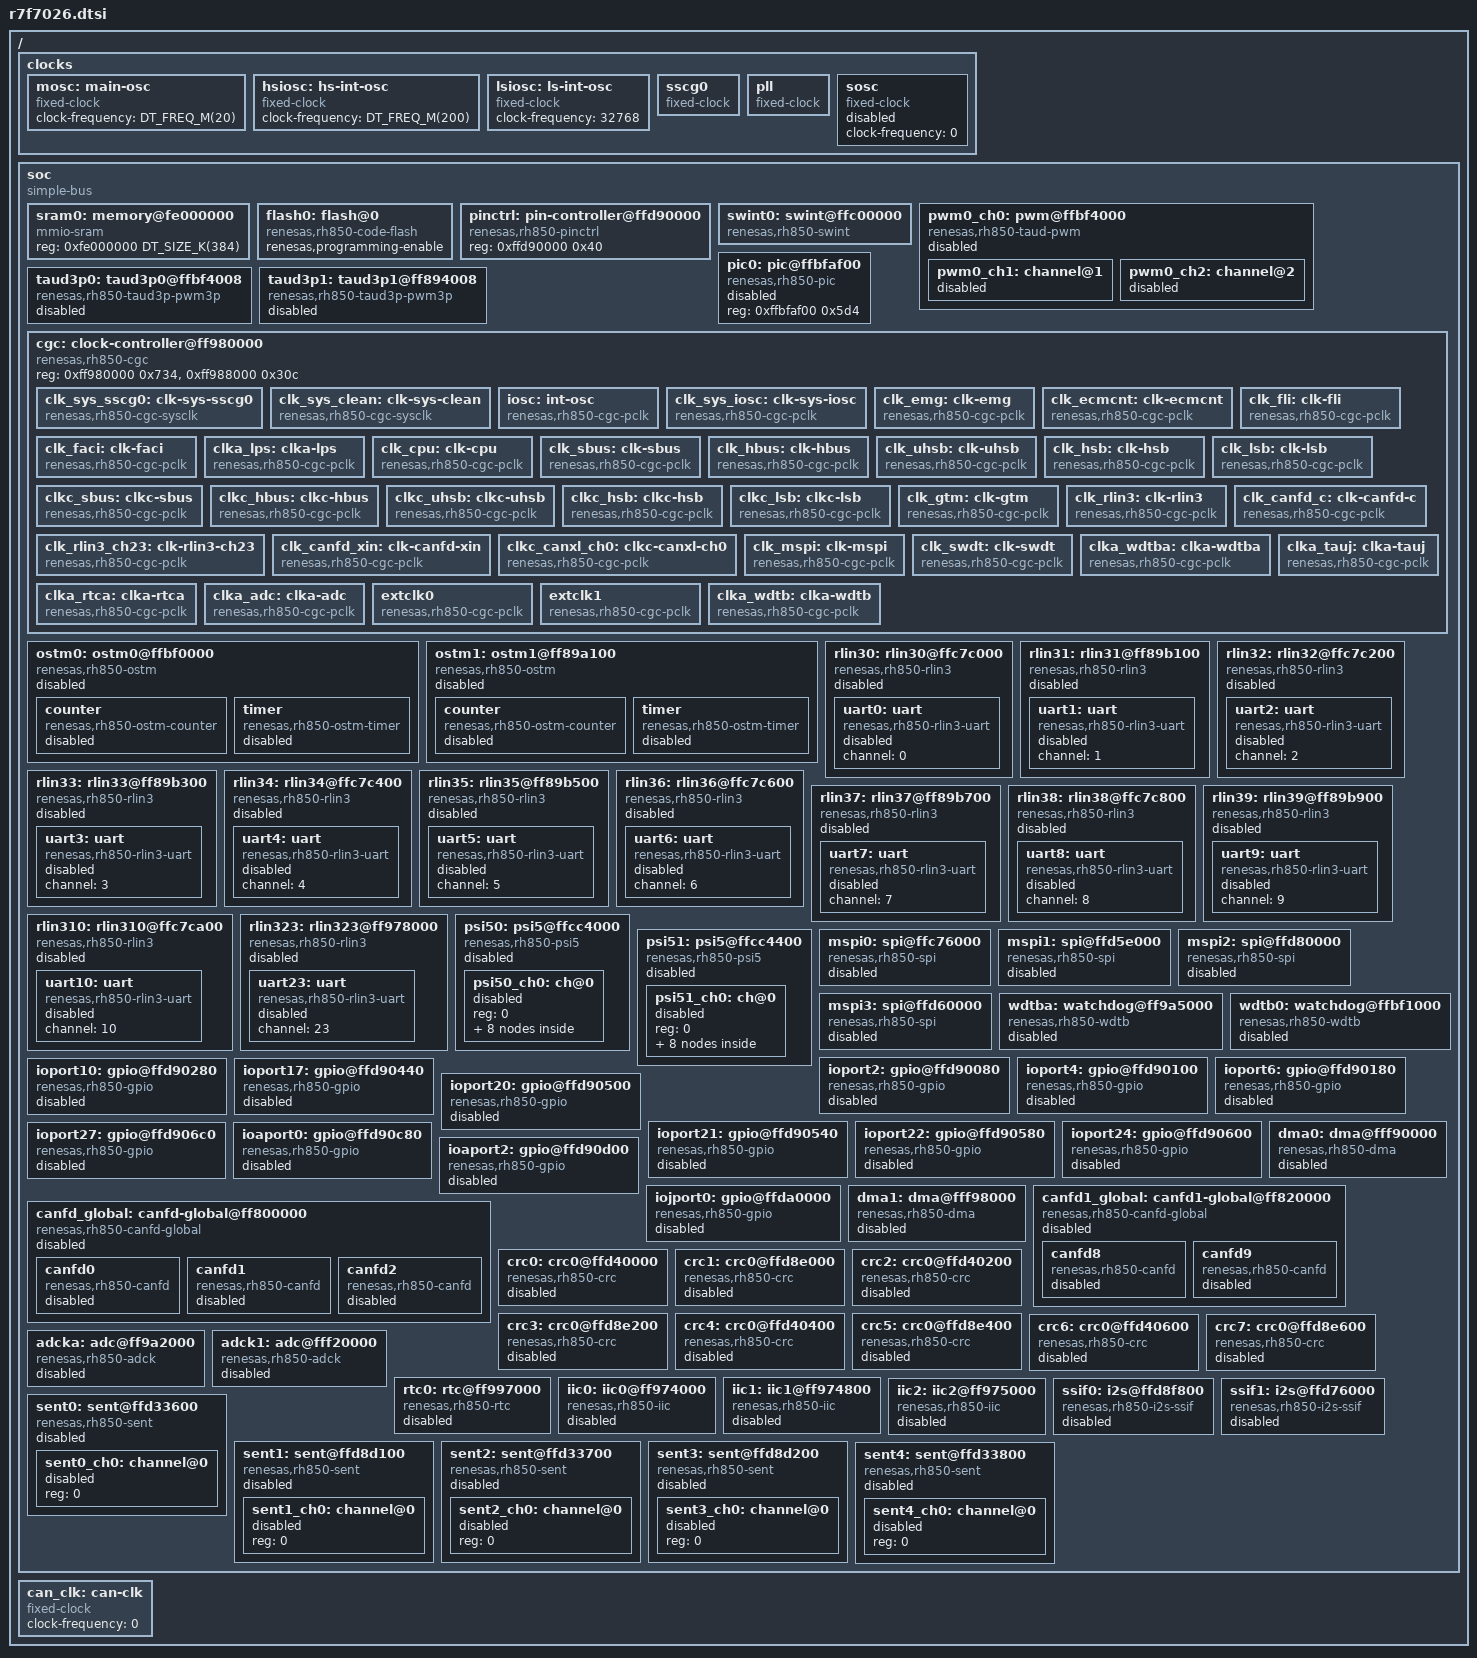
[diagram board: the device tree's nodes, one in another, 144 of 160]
/*
 * Copyright (c) 2026 Renesas Electronics Corporation
 *
 * SPDX-License-Identifier: Apache-2.0
 */

#include <rh850/renesas/rh850u2c/u2c-g4kh-common.dtsi>
#include <zephyr/dt-bindings/clock/renesas_rh850u2c_clock.h>
#include <zephyr/dt-bindings/gpio/gpio.h>
#include <freq.h>

/ {
	clocks {
		mosc: main-osc {
			compatible = "fixed-clock";
			#clock-cells = <0>;
			status = "okay";
			clock-frequency = <DT_FREQ_M(20)>;
		};

		hsiosc: hs-int-osc {
			compatible = "fixed-clock";
			#clock-cells = <0>;
			status = "okay";
			clock-frequency = <DT_FREQ_M(200)>;
		};

		lsiosc: ls-int-osc {
			compatible = "fixed-clock";
			#clock-cells = <0>;
			status = "okay";
			clock-frequency = <32768>;
		};

		sscg0: sscg0 {
			compatible = "fixed-clock";
			#clock-cells = <0>;
			status = "okay";
			clock-frequency = <DT_FREQ_M(640)>;
			clocks = <&mosc>;
		};

		pll: pll {
			compatible = "fixed-clock";
			#clock-cells = <0>;
			status = "okay";
			clock-frequency = <DT_FREQ_M(800)>;
			clocks = <&mosc>;
		};

		sosc: sosc {
			compatible = "fixed-clock";
			#clock-cells = <0>;
			status = "disabled";
			clock-frequency = <0>;
		};
	};

	soc {
		#address-cells = <1>;
		#size-cells = <1>;
		compatible = "simple-bus";
		ranges;

		sram0: memory@fe000000 {
			compatible = "mmio-sram";
			reg = <0xfe000000 DT_SIZE_K(384)>;
		};

		flash0: flash@0 {
			compatible = "renesas,rh850-code-flash";
			renesas,programming-enable;
		};

		pinctrl: pin-controller@ffd90000 {
			compatible = "renesas,rh850-pinctrl";
			reg = <0xffd90000 0x40>;
			status = "okay";
		};

		swint0: swint@ffc00000 {
			compatible = "renesas,rh850-swint";
			reg = <0xffc00000 0x01>;
			interrupts-extended = <&intc1_pe0 14 14>,
					      <&intc1_pe1 14 14>;
			interrupt-names = "swint_pe0", "swint_pe1";
			status = "okay";
		};

		pwm0_ch0: pwm@ffbf4000 {
			compatible = "renesas,rh850-taud-pwm";
			reg = <0xffbf4000 0x100>;
			unit = <0>;
			channel = <0>;
			interrupt-parent = <&intc1_pe0>;
			clocks = <&cgc RH850_PCLK(TAUD, 0, PCLK)>;
			clock-source = <0>;
			clock-divider = <5>;
			interrupts = <10 1>;
			#pwm-cells = <3>;
			#address-cells = <1>;
			#size-cells = <0>;
			status = "disabled";

			pwm0_ch1: channel@1 {
				reg = <1>;
				channel-mode = "synchronized";
				status = "disabled";
			};

			pwm0_ch2: channel@2 {
				reg = <2>;
				channel-mode = "synchronized";
				status = "disabled";
			};
		};

		pic0: pic@ffbfaf00 {
			compatible = "renesas,rh850-pic";
			reg = <0xffbfaf00 0x5d4>;
			status = "disabled";
		};

		taud3p0: taud3p0@ffbf4008 {
			compatible = "renesas,rh850-taud3p-pwm3p";
			reg = <0xffbf4008 0x2000>;
			taud-three-phase-unit = <0>;
			clocks = <&cgc RH850_PCLK(TAUD, 0, PCLK)>;
			period-counts = <0xfa0>;
			deadtime-counts = <240>;
			operation-clk = <0>;
			clk-div = <0>;
			interrupts = <11 1>;
			interrupt-parent = <&intc2>;
			status = "disabled";
		};

		taud3p1: taud3p1@ff894008 {
			compatible = "renesas,rh850-taud3p-pwm3p";
			reg = <0xff894008 0x2000>;
			taud-three-phase-unit = <1>;
			clocks = <&cgc RH850_PCLK(TAUD, 1, PCLK)>;
			period-counts = <0xfa0>;
			deadtime-counts = <240>;
			operation-clk = <0>;
			clk-div = <0>;
			interrupts = <159 1>;
			interrupt-parent = <&intc2>;
			status = "disabled";
		};

		cgc: clock-controller@ff980000 {
			compatible = "renesas,rh850-cgc";
			reg = <0xff980000 0x734>, <0xff988000 0x30c>;
			#clock-cells = <1>;
			status = "okay";

			clk_sys_sscg0: clk-sys-sscg0 {
				compatible = "renesas,rh850-cgc-sysclk";
				clock-source = <&sscg0>;
				#clock-cells = <0>;
				status = "okay";
				modulation-value = <30>;
				modulation-dithered-range = <0>;
				renesas,cyclicrun-clock-source = <&clk_sys_iosc>;
				div = <1>;
				renesas,cyclicrun-div = <1>;
			};

			clk_sys_clean: clk-sys-clean {
				compatible = "renesas,rh850-cgc-sysclk";
				clock-source = <&pll>;
				#clock-cells = <0>;
				status = "okay";
				renesas,cyclicrun-clock-source = <&clk_sys_iosc>;
				div = <1>;
				renesas,cyclicrun-div = <1>;
			};

			iosc: int-osc {
				compatible = "renesas,rh850-cgc-pclk";
				#clock-cells = <0>;
				status = "okay";
				clock-source = <&hsiosc>;
				div = <1>;
			};

			clk_sys_iosc: clk-sys-iosc {
				compatible = "renesas,rh850-cgc-pclk";
				#clock-cells = <0>;
				status = "okay";
				clock-source = <&hsiosc>;
				div = <1>;
			};

			clk_emg: clk-emg {
				compatible = "renesas,rh850-cgc-pclk";
				#clock-cells = <0>;
				status = "okay";
				clock-source = <&hsiosc>;
				renesas,cyclicrun-clock-source = <&hsiosc>;
				div = <20>;
				renesas,cyclicrun-div = <20>;
			};

			clk_ecmcnt: clk-ecmcnt {
				compatible = "renesas,rh850-cgc-pclk";
				#clock-cells = <0>;
				status = "okay";
				clock-source = <&hsiosc>;
				div = <20>;
			};

			clk_fli: clk-fli {
				compatible = "renesas,rh850-cgc-pclk";
				#clock-cells = <0>;
				status = "okay";
				clock-source = <&clk_cpu>;
				div = <1>;
			};

			clk_faci: clk-faci {
				compatible = "renesas,rh850-cgc-pclk";
				#clock-cells = <0>;
				status = "okay";
				clock-source = <&clk_lsb>;
				div = <1>;
			};

			clka_lps: clka-lps {
				compatible = "renesas,rh850-cgc-pclk";
				#clock-cells = <0>;
				status = "okay";
				clock-source = <&hsiosc>;
				div = <20>;
			};

			clk_cpu: clk-cpu {
				compatible = "renesas,rh850-cgc-pclk";
				#clock-cells = <0>;
				status = "okay";
				clock-source = <&clk_sys_sscg0>;
				div = <2>;
			};

			clk_sbus: clk-sbus {
				compatible = "renesas,rh850-cgc-pclk";
				#clock-cells = <0>;
				status = "okay";
				clock-source = <&clk_sys_sscg0>;
				div = <4>;
			};

			clk_hbus: clk-hbus {
				compatible = "renesas,rh850-cgc-pclk";
				#clock-cells = <0>;
				status = "okay";
				clock-source = <&clk_sys_sscg0>;
				div = <8>;
			};

			clk_uhsb: clk-uhsb {
				compatible = "renesas,rh850-cgc-pclk";
				#clock-cells = <0>;
				status = "okay";
				clock-source = <&clk_sys_sscg0>;
				div = <4>;
			};

			clk_hsb: clk-hsb {
				compatible = "renesas,rh850-cgc-pclk";
				#clock-cells = <0>;
				status = "okay";
				clock-source = <&clk_sys_sscg0>;
				div = <8>;
			};

			clk_lsb: clk-lsb {
				compatible = "renesas,rh850-cgc-pclk";
				#clock-cells = <0>;
				status = "okay";
				clock-source = <&clk_sys_sscg0>;
				div = <16>;
			};

			clkc_sbus: clkc-sbus {
				compatible = "renesas,rh850-cgc-pclk";
				#clock-cells = <0>;
				status = "okay";
				clock-source = <&clk_sys_clean>;
				div = <4>;
			};

			clkc_hbus: clkc-hbus {
				compatible = "renesas,rh850-cgc-pclk";
				#clock-cells = <0>;
				status = "okay";
				clock-source = <&clk_sys_clean>;
				div = <8>;
			};

			clkc_uhsb: clkc-uhsb {
				compatible = "renesas,rh850-cgc-pclk";
				#clock-cells = <0>;
				status = "okay";
				clock-source = <&clk_sys_clean>;
				div = <5>;
			};

			clkc_hsb: clkc-hsb {
				compatible = "renesas,rh850-cgc-pclk";
				#clock-cells = <0>;
				status = "okay";
				clock-source = <&clk_sys_clean>;
				div = <10>;
			};

			clkc_lsb: clkc-lsb {
				compatible = "renesas,rh850-cgc-pclk";
				#clock-cells = <0>;
				status = "okay";
				clock-source = <&clk_sys_clean>;
				div = <20>;
			};

			clk_gtm: clk-gtm {
				compatible = "renesas,rh850-cgc-pclk";
				#clock-cells = <0>;
				status = "okay";
				clock-source = <&clkc_sbus>;
				div = <1>;
			};

			clk_rlin3: clk-rlin3 {
				compatible = "renesas,rh850-cgc-pclk";
				clock-source = <&clkc_hsb>;
				#clock-cells = <0>;
				status = "okay";
				renesas,cyclicrun-clock-source = <&clkc_hsb>;
				div = <1>;
				renesas,cyclicrun-div = <1>;
			};

			clk_rlin3_ch23: clk-rlin3-ch23 {
				compatible = "renesas,rh850-cgc-pclk";
				clock-source = <&clkc_hbus>;
				#clock-cells = <0>;
				status = "okay";
				renesas,cyclicrun-clock-source = <&clkc_hbus>;
				div = <1>;
				renesas,cyclicrun-div = <1>;
			};

			clk_canfd_c: clk-canfd-c {
				compatible = "renesas,rh850-cgc-pclk";
				clock-source = <&clkc_hsb>;
				#clock-cells = <0>;
				status = "okay";
				div = <1>;
			};

			clk_canfd_xin: clk-canfd-xin {
				compatible = "renesas,rh850-cgc-pclk";
				clock-source = <&mosc>;
				#clock-cells = <0>;
				status = "okay";
				div = <1>;
			};

			clkc_canxl_ch0: clkc-canxl-ch0 {
				compatible = "renesas,rh850-cgc-pclk";
				clock-source = <&clkc_hsb>;
				#clock-cells = <0>;
				status = "okay";
				div = <1>;
			};

			clk_mspi: clk-mspi {
				compatible = "renesas,rh850-cgc-pclk";
				clock-source = <&clkc_hsb>;
				#clock-cells = <0>;
				status = "okay";
				renesas,cyclicrun-clock-source = <&clkc_hsb>;
				div = <1>;
				renesas,cyclicrun-div = <1>;
			};

			clk_swdt: clk-swdt {
				compatible = "renesas,rh850-cgc-pclk";
				clock-source = <&hsiosc>;
				#clock-cells = <0>;
				status = "okay";
				div = <20>;
			};

			clka_wdtba: clka-wdtba {
				compatible = "renesas,rh850-cgc-pclk";
				clock-source = <&lsiosc>;
				#clock-cells = <0>;
				status = "okay";
				renesas,cyclicrun-clock-source = <&lsiosc>;
				div = <128>;
				renesas,cyclicrun-div = <128>;
			};

			clka_tauj: clka-tauj {
				compatible = "renesas,rh850-cgc-pclk";
				clock-source = <&lsiosc>;
				#clock-cells = <0>;
				status = "okay";
				renesas,cyclicrun-clock-source = <&lsiosc>;
				div = <1>;
				renesas,cyclicrun-div = <1>;
			};

			clka_rtca: clka-rtca {
				compatible = "renesas,rh850-cgc-pclk";
				clock-source = <&lsiosc>;
				#clock-cells = <0>;
				status = "okay";
				renesas,cyclicrun-clock-source = <&lsiosc>;
				div = <1>;
				renesas,cyclicrun-div = <1>;
			};

			clka_adc: clka-adc {
				compatible = "renesas,rh850-cgc-pclk";
				clock-source = <&hsiosc>;
				#clock-cells = <0>;
				status = "okay";
				renesas,cyclicrun-clock-source = <&hsiosc>;
				div = <20>;
				renesas,cyclicrun-div = <20>;
			};

			extclk0: extclk0 {
				compatible = "renesas,rh850-cgc-pclk";
				clock-source = <&clk_hsb>;
				div = <0>;
				#clock-cells = <0>;
				status = "okay";
				renesas,cyclicrun-div = <0>;
				renesas,cyclicrun-clock-source = <&clk_hsb>;
			};

			extclk1: extclk1 {
				compatible = "renesas,rh850-cgc-pclk";
				clock-source = <&clk_hsb>;
				div = <0>;
				#clock-cells = <0>;
				status = "okay";
				renesas,cyclicrun-div = <0>;
				renesas,cyclicrun-clock-source = <&clk_hsb>;
			};

			clka_wdtb: clka-wdtb {
				compatible = "renesas,rh850-cgc-pclk";
				clock-source = <&hsiosc>;
				#clock-cells = <0>;
				status = "okay";
				div = <640>;
				renesas,cyclicrun-clock-source = <&hsiosc>;
				renesas,cyclicrun-div = <640>;
			};
		};

		ostm0: ostm0@ffbf0000 {
			compatible = "renesas,rh850-ostm";
			reg = <0xffbf0000 0x20>;
			channel = <0>;
			interrupts = <63 1>;
			interrupt-names = "overflow";
			interrupt-parent = <&intc2>;
			clocks = <&cgc RH850_PCLK(OSTM, 0, PCLK)>;
			status = "disabled";

			counter {
				compatible = "renesas,rh850-ostm-counter";
				status = "disabled";
			};

			timer {
				compatible = "renesas,rh850-ostm-timer";
				status = "disabled";
			};
		};

		ostm1: ostm1@ff89a100 {
			compatible = "renesas,rh850-ostm";
			reg = <0xff89a100 0x20>;
			channel = <1>;
			interrupts = <484 1>;
			interrupt-names = "overflow";
			interrupt-parent = <&intc2>;
			clocks = <&cgc RH850_PCLK(OSTM, 1, PCLK)>;
			status = "disabled";

			counter {
				compatible = "renesas,rh850-ostm-counter";
				status = "disabled";
			};

			timer {
				compatible = "renesas,rh850-ostm-timer";
				status = "disabled";
			};
		};

		rlin30: rlin30@ffc7c000 {
			compatible = "renesas,rh850-rlin3";
			interrupts = <173 1>, <174 1>, <175 1>, <176 1>;
			interrupt-names = "rlin3i", "txi", "rxi", "eri";
			reg = <0xffc7c000 0x35>;
			interrupt-parent = <&intc2>;
			clocks = <&cgc RH850_PCLK(RLIN3, 0, RLIN3)>;
			status = "disabled";

			uart0: uart {
				compatible = "renesas,rh850-rlin3-uart";
				channel = <0>;
				status = "disabled";
			};
		};

		rlin31: rlin31@ff89b100 {
			compatible = "renesas,rh850-rlin3";
			interrupts = <178 1>, <179 1>, <180 1>, <181 1>;
			interrupt-names = "rlin3i", "txi", "rxi", "eri";
			reg = <0xff89b100 0x35>;
			interrupt-parent = <&intc2>;
			clocks = <&cgc RH850_PCLK(RLIN3, 1, RLIN3)>;
			status = "disabled";

			uart1: uart {
				compatible = "renesas,rh850-rlin3-uart";
				channel = <1>;
				status = "disabled";
			};
		};

		rlin32: rlin32@ffc7c200 {
			compatible = "renesas,rh850-rlin3";
			interrupts = <183 1>, <184 1>, <185 1>, <186 1>;
			interrupt-names = "rlin3i", "txi", "rxi", "eri";
			reg = <0xffc7c200 0x35>;
			interrupt-parent = <&intc2>;
			clocks = <&cgc RH850_PCLK(RLIN3, 2, RLIN3)>;
			status = "disabled";

			uart2: uart {
				compatible = "renesas,rh850-rlin3-uart";
				channel = <2>;
				status = "disabled";
			};
		};

		rlin33: rlin33@ff89b300 {
			compatible = "renesas,rh850-rlin3";
			interrupts = <188 1>, <189 1>, <190 1>, <191 1>;
			interrupt-names = "rlin3i", "txi", "rxi", "eri";
			reg = <0xff89b300 0x35>;
			interrupt-parent = <&intc2>;
			clocks = <&cgc RH850_PCLK(RLIN3, 3, RLIN3)>;
			status = "disabled";

			uart3: uart {
				compatible = "renesas,rh850-rlin3-uart";
				channel = <3>;
				status = "disabled";
			};
		};

		rlin34: rlin34@ffc7c400 {
			compatible = "renesas,rh850-rlin3";
			interrupts = <193 1>, <194 1>, <195 1>, <196 1>;
			interrupt-names = "rlin3i", "txi", "rxi", "eri";
			reg = <0xffc7c400 0x35>;
			interrupt-parent = <&intc2>;
			clocks = <&cgc RH850_PCLK(RLIN3, 4, RLIN3)>;
			status = "disabled";

			uart4: uart {
				compatible = "renesas,rh850-rlin3-uart";
				channel = <4>;
				status = "disabled";
			};
		};

		rlin35: rlin35@ff89b500 {
			compatible = "renesas,rh850-rlin3";
			interrupts = <197 1>, <198 1>, <199 1>, <200 1>;
			interrupt-names = "rlin3i", "txi", "rxi", "eri";
			reg = <0xff89b500 0x35>;
			interrupt-parent = <&intc2>;
			clocks = <&cgc RH850_PCLK(RLIN3, 5, RLIN3)>;
			status = "disabled";

			uart5: uart {
				compatible = "renesas,rh850-rlin3-uart";
				channel = <5>;
				status = "disabled";
			};
		};

		rlin36: rlin36@ffc7c600 {
			compatible = "renesas,rh850-rlin3";
			interrupts = <201 1>, <202 1>, <203 1>, <204 1>;
			interrupt-names = "rlin3i", "txi", "rxi", "eri";
			reg = <0xffc7c600 0x35>;
			interrupt-parent = <&intc2>;
			clocks = <&cgc RH850_PCLK(RLIN3, 6, RLIN3)>;
			status = "disabled";

			uart6: uart {
				compatible = "renesas,rh850-rlin3-uart";
				channel = <6>;
				status = "disabled";
			};
		};

		rlin37: rlin37@ff89b700 {
			compatible = "renesas,rh850-rlin3";
			interrupts = <394 1>, <395 1>, <396 1>, <397 1>;
			interrupt-names = "rlin3i", "txi", "rxi", "eri";
			reg = <0xff89b700 0x35>;
			interrupt-parent = <&intc2>;
			clocks = <&cgc RH850_PCLK(RLIN3, 7, RLIN3)>;
			status = "disabled";

			uart7: uart {
				compatible = "renesas,rh850-rlin3-uart";
				channel = <7>;
				status = "disabled";
			};
		};

		rlin38: rlin38@ffc7c800 {
			compatible = "renesas,rh850-rlin3";
			interrupts = <398 1>, <399 1>, <400 1>, <401 1>;
			interrupt-names = "rlin3i", "txi", "rxi", "eri";
			reg = <0xffc7c800 0x35>;
			interrupt-parent = <&intc2>;
			clocks = <&cgc RH850_PCLK(RLIN3, 8, RLIN3)>;
			status = "disabled";

			uart8: uart {
				compatible = "renesas,rh850-rlin3-uart";
				channel = <8>;
				status = "disabled";
			};
		};

		rlin39: rlin39@ff89b900 {
			compatible = "renesas,rh850-rlin3";
			interrupts = <402 1>, <403 1>, <404 1>, <405 1>;
			interrupt-names = "rlin3i", "txi", "rxi", "eri";
			reg = <0xff89b900 0x35>;
			interrupt-parent = <&intc2>;
			clocks = <&cgc RH850_PCLK(RLIN3, 9, RLIN3)>;
			status = "disabled";

			uart9: uart {
				compatible = "renesas,rh850-rlin3-uart";
				channel = <9>;
				status = "disabled";
			};
		};

		rlin310: rlin310@ffc7ca00 {
			compatible = "renesas,rh850-rlin3";
			interrupts = <406 1>, <407 1>, <408 1>, <409 1>;
			interrupt-names = "rlin3i", "txi", "rxi", "eri";
			reg = <0xffc7ca00 0x35>;
			interrupt-parent = <&intc2>;
			clocks = <&cgc RH850_PCLK(RLIN3, 10, RLIN3)>;
			status = "disabled";

			uart10: uart {
				compatible = "renesas,rh850-rlin3-uart";
				channel = <10>;
				status = "disabled";
			};
		};

		rlin323: rlin323@ff978000 {
			compatible = "renesas,rh850-rlin3";
			interrupts = <205 1>, <206 1>, <207 1>, <208 1>;
			interrupt-names = "rlin3i", "txi", "rxi", "eri";
			reg = <0xff978000 0x35>;
			interrupt-parent = <&intc2>;
			clocks = <&cgc RH850_PCLK(RLIN3, 23, CH23_RLIN3)>;
			status = "disabled";

			uart23: uart {
				compatible = "renesas,rh850-rlin3-uart";
				channel = <23>;
				status = "disabled";
			};
		};

		psi50: psi5@ffcc4000 {
			compatible = "renesas,rh850-psi5";
			reg = <0xffcc4000 0x400>;
			interrupts = <419 1>, <420 1>, <421 1>;
			interrupt-names = "status", "rx", "tx";
			interrupt-parent = <&intc2>;
			clocks = <&cgc RH850_PCLK(PSI5, 0, PCLK)>;
			renesas,unit-id = <0>;
			#address-cells = <1>;
			#size-cells = <0>;
			status = "disabled";

			psi50_ch0: ch@0 {
				reg = <0>;
				#address-cells = <1>;
				#size-cells = <0>;
				status = "disabled";

				psi50_ch0_rx_slot0: slot@0 {
					reg = <0>;
					status = "disabled";
				};

				psi50_ch0_rx_slot1: slot@1 {
					reg = <1>;
					status = "disabled";
				};

				psi50_ch0_rx_slot2: slot@2 {
					reg = <2>;
					status = "disabled";
				};

				psi50_ch0_rx_slot3: slot@3 {
					reg = <3>;
					status = "disabled";
				};

				psi50_ch0_rx_slot4: slot@4 {
					reg = <4>;
					status = "disabled";
				};

				psi50_ch0_rx_slot5: slot@5 {
					reg = <5>;
					status = "disabled";
				};

				psi50_ch0_rx_slot6: slot@6 {
					reg = <6>;
					status = "disabled";
				};

				psi50_ch0_rx_slot7: slot@7 {
					reg = <7>;
					status = "disabled";
				};
			};
		};

		psi51: psi5@ffcc4400 {
			compatible = "renesas,rh850-psi5";
			reg = <0xffcc4400 0x400>;
			interrupts = <422 1>, <423 1>, <424 1>;
			interrupt-names = "status", "rx", "tx";
			interrupt-parent = <&intc2>;
			clocks = <&cgc RH850_PCLK(PSI5, 1, PCLK)>;
			renesas,unit-id = <1>;
			#address-cells = <1>;
			#size-cells = <0>;
			status = "disabled";

			psi51_ch0: ch@0 {
				reg = <0>;
				#address-cells = <1>;
				#size-cells = <0>;
				status = "disabled";

				psi51_ch0_rx_slot0: slot@0 {
					reg = <0>;
					status = "disabled";
				};

				psi51_ch0_rx_slot1: slot@1 {
					reg = <1>;
					status = "disabled";
				};

				psi51_ch0_rx_slot2: slot@2 {
					reg = <2>;
					status = "disabled";
				};

				psi51_ch0_rx_slot3: slot@3 {
					reg = <3>;
					status = "disabled";
				};

				psi51_ch0_rx_slot4: slot@4 {
					reg = <4>;
					status = "disabled";
				};

				psi51_ch0_rx_slot5: slot@5 {
					reg = <5>;
					status = "disabled";
				};

				psi51_ch0_rx_slot6: slot@6 {
					reg = <6>;
					status = "disabled";
				};

				psi51_ch0_rx_slot7: slot@7 {
					reg = <7>;
					status = "disabled";
				};
			};
		};

		mspi0: spi@ffc76000 {
			compatible = "renesas,rh850-spi";
			interrupts-extended = <&intc2 76 1>,
					      <&intc2 79 1>,
					      <&mspite_ored0>,
					      <&mspier_ored0>;
			interrupt-names = "txi", "rxi", "tei", "eri";
			reg = <0xffc76000 0x680>;
			#address-cells = <1>;
			#size-cells = <0>;
			unit = <0>;
			channel = <0>;
			status = "disabled";
		};

		mspi1: spi@ffd5e000 {
			compatible = "renesas,rh850-spi";
			interrupts-extended = <&mspitx_ored1>,
					      <&mspirx_ored1>,
					      <&mspite_ored1>,
					      <&mspier_ored1>;
			interrupt-names = "txi", "rxi", "tei", "eri";
			reg = <0xffd5e000 0x680>;
			#address-cells = <1>;
			#size-cells = <0>;
			unit = <1>;
			channel = <0>;
			status = "disabled";
		};

		mspi2: spi@ffd80000 {
			compatible = "renesas,rh850-spi";
			interrupts-extended = <&mspitx_ored2>,
					      <&mspirx_ored2>,
					      <&mspite_ored2>,
					      <&mspier_ored2>;
			interrupt-names = "txi", "rxi", "tei", "eri";
			reg = <0xffd80000 0x680>;
			#address-cells = <1>;
			#size-cells = <0>;
			unit = <2>;
			channel = <0>;
			status = "disabled";
		};

		mspi3: spi@ffd60000 {
			compatible = "renesas,rh850-spi";
			interrupts-extended = <&mspitx_ored3>,
					      <&mspirx_ored3>,
					      <&mspite_ored3>,
					      <&mspier_ored3>;
			interrupt-names = "txi", "rxi", "tei", "eri";
			reg = <0xffd60000 0x680>;
			#address-cells = <1>;
			#size-cells = <0>;
			unit = <3>;
			channel = <0>;
			status = "disabled";
		};

		wdtba: watchdog@ff9a5000 {
			unit = <0>;
			compatible = "renesas,rh850-wdtb";
			interrupts = <306 0>;
			window-open-mode = "select-by-window-start";
			error-mode = "nmi-mode";
			clock-freq = <256>;
			reg = <0xff9a5000 0x14>;
			interrupt-parent = <&intc2>;
			status = "disabled";
		};

		wdtb0: watchdog@ffbf1000 {
			unit = <1>;
			compatible = "renesas,rh850-wdtb";
			interrupts = <22 0>;
			window-open-mode = "select-by-window-start";
			error-mode = "nmi-mode";
			clock-freq = <312500>;
			reg = <0xffbf1000 0x14>;
			interrupt-parent = <&intc2>;
			status = "disabled";
		};

		ioport2: gpio@ffd90080 {
			compatible = "renesas,rh850-gpio";
			reg = <0xffd90080 0x40>;
			port = <2>;
			protected-write-mask = <2>;
			port-type = "port";
			#gpio-cells = <2>;
			gpio-controller;
			status = "disabled";
		};

		ioport4: gpio@ffd90100 {
			compatible = "renesas,rh850-gpio";
			reg = <0xffd90100 0x40>;
			port = <4>;
			protected-write-mask = <4>;
			port-type = "port";
			#gpio-cells = <2>;
			gpio-controller;
			status = "disabled";
		};

		ioport6: gpio@ffd90180 {
			compatible = "renesas,rh850-gpio";
			reg = <0xffd90180 0x40>;
			port = <6>;
			protected-write-mask = <6>;
			port-type = "port";
			#gpio-cells = <2>;
			gpio-controller;
			status = "disabled";
		};

		ioport10: gpio@ffd90280 {
			compatible = "renesas,rh850-gpio";
			reg = <0xffd90280 0x40>;
			port = <10>;
			protected-write-mask = <8>;
			port-type = "port";
			#gpio-cells = <2>;
			gpio-controller;
			status = "disabled";
		};

		ioport17: gpio@ffd90440 {
			compatible = "renesas,rh850-gpio";
			reg = <0xffd90440 0x40>;
			port = <17>;
			protected-write-mask = <10>;
			port-type = "port";
			#gpio-cells = <2>;
			gpio-controller;
			status = "disabled";
		};

		ioport20: gpio@ffd90500 {
			compatible = "renesas,rh850-gpio";
			reg = <0xffd90500 0x40>;
			port = <20>;
			protected-write-mask = <12>;
			port-type = "port";
			#gpio-cells = <2>;
			gpio-controller;
			status = "disabled";
		};

		ioport21: gpio@ffd90540 {
			compatible = "renesas,rh850-gpio";
			reg = <0xffd90540 0x40>;
			port = <21>;
			protected-write-mask = <13>;
			port-type = "port";
			#gpio-cells = <2>;
			gpio-controller;
			status = "disabled";
		};

		ioport22: gpio@ffd90580 {
			compatible = "renesas,rh850-gpio";
			reg = <0xffd90580 0x40>;
			port = <22>;
			protected-write-mask = <14>;
			port-type = "port";
			#gpio-cells = <2>;
			gpio-controller;
			status = "disabled";
		};

		ioport24: gpio@ffd90600 {
			compatible = "renesas,rh850-gpio";
			reg = <0xffd90600 0x40>;
			port = <24>;
			protected-write-mask = <15>;
			port-type = "port";
			#gpio-cells = <2>;
			gpio-controller;
			status = "disabled";
		};

		ioport27: gpio@ffd906c0 {
			compatible = "renesas,rh850-gpio";
			reg = <0xffd906c0 0x40>;
			port = <27>;
			protected-write-mask = <16>;
			port-type = "port";
			#gpio-cells = <2>;
			gpio-controller;
			status = "disabled";
		};

		ioaport0: gpio@ffd90c80 {
			compatible = "renesas,rh850-gpio";
			reg = <0xffd90c80 0x40>;
			port = <0>;
			protected-write-mask = <20>;
			port-type = "aport";
			#gpio-cells = <2>;
			gpio-controller;
			status = "disabled";
		};

		ioaport2: gpio@ffd90d00 {
			compatible = "renesas,rh850-gpio";
			reg = <0xffd90d00 0x40>;
			port = <2>;
			protected-write-mask = <22>;
			port-type = "aport";
			#gpio-cells = <2>;
			gpio-controller;
			status = "disabled";
		};

		iojport0: gpio@ffda0000 {
			compatible = "renesas,rh850-gpio";
			reg = <0xffda0000 0x40>;
			port = <0>;
			protected-write-mask = <255>;
			port-type = "jport";
			#gpio-cells = <2>;
			gpio-controller;
			status = "disabled";
		};

		dma0: dma@fff90000 {
			compatible = "renesas,rh850-dma";
			reg = <0xfff90000 0x5000>, <0xfff95000 0x020>;
			reg-names = "reg_main", "ext";
			interrupts = <41 1>, <42 1>, <43 1>, <44 1>,
				     <45 1>, <46 1>, <47 1>, <48 1>,
				     <49 1>, <50 1>, <51 1>, <52 1>,
				     <53 1>, <54 1>, <55 1>, <56 1>;
			interrupt-names = "ch0", "ch1", "ch2", "ch3",
					  "ch4", "ch5", "ch6", "ch7",
					  "ch8", "ch9", "ch10", "ch11",
					  "ch12", "ch13", "ch14", "ch15";
			interrupt-parent = <&intc2>;
			dma-unit = <0>;
			dma-channels = <16>;
			#dma-cells = <3>;
			status = "disabled";
		};

		dma1: dma@fff98000 {
			compatible = "renesas,rh850-dma";
			reg = <0xfff98000 0x5000>, <0xfff9d000 0x020>;
			reg-names = "reg_main", "ext";
			interrupts = <320 1>, <321 1>, <322 1>, <323 1>,
				     <324 1>, <325 1>, <326 1>, <327 1>,
				     <328 1>, <329 1>, <330 1>, <331 1>,
				     <332 1>, <333 1>, <334 1>, <335 1>;
			interrupt-names = "ch0", "ch1", "ch2", "ch3",
					  "ch4", "ch5", "ch6", "ch7",
					  "ch8", "ch9", "ch10", "ch11",
					  "ch12", "ch13", "ch14", "ch15";
			interrupt-parent = <&intc2>;
			dma-unit = <1>;
			dma-channels = <16>;
			#dma-cells = <3>;
			status = "disabled";
		};

		canfd_global: canfd-global@ff800000 {
			compatible = "renesas,rh850-canfd-global";
			unit = <0>;
			reg = <0xff800000 DT_SIZE_K(128)>;
			interrupts = <104 1>, <105 1>;
			interrupt-names = "g_err", "g_recc";
			interrupt-parent = <&intc2>;
			clocks = <&cgc RH850_PCLK(RSCFD, 0, CANFD_C)>;
			status = "disabled";

			canfd0: canfd0 {
				compatible = "renesas,rh850-canfd";
				channel = <0>;
				interrupts-extended = <&canfderi_ored0>,
						      <&canfdrxi_ored0>,
						      <&canfdtxi_ored0>;
				interrupt-names = "eri", "rxi", "txi";
				status = "disabled";
			};

			canfd1: canfd1 {
				compatible = "renesas,rh850-canfd";
				channel = <1>;
				interrupts-extended = <&canfderi_ored0>,
						      <&canfdrxi_ored0>,
						      <&canfdtxi_ored0>;
				interrupt-names = "eri", "rxi", "txi";
				status = "disabled";
			};

			canfd2: canfd2 {
				compatible = "renesas,rh850-canfd";
				channel = <2>;
				interrupts-extended = <&canfderi_ored0>,
						      <&canfdrxi_ored0>,
						      <&canfdtxi_ored0>;
				interrupt-names = "eri", "rxi", "txi";
				status = "disabled";
			};
		};

		canfd1_global: canfd1-global@ff820000 {
			compatible = "renesas,rh850-canfd-global";
			unit = <1>;
			reg = <0xff820000 DT_SIZE_K(128)>;
			interrupts = <566 1>, <567 1>;
			interrupt-names = "g_err", "g_recc";
			interrupt-parent = <&intc2>;
			clocks = <&cgc RH850_PCLK(RSCFD, 1, CANFD_C)>;
			status = "disabled";

			canfd8: canfd8 {
				compatible = "renesas,rh850-canfd";
				channel = <8>;
				interrupts-extended = <&canfderi_ored0>,
						      <&canfdrxi_ored0>,
						      <&canfdtxi_ored0>;
				interrupt-names = "eri", "rxi", "txi";
				status = "disabled";
			};

			canfd9: canfd9 {
				compatible = "renesas,rh850-canfd";
				channel = <9>;
				interrupts-extended = <&canfderi_ored0>,
						      <&canfdrxi_ored0>,
						      <&canfdtxi_ored0>;
				interrupt-names = "eri", "rxi", "txi";
				status = "disabled";
			};
		};

		crc0: crc0@ffd40000 {
			compatible = "renesas,rh850-crc";
			reg = <0xffd40000 0xb8>;
			channel = <0>;
			status = "disabled";
		};

		crc1: crc0@ffd8e000 {
			compatible = "renesas,rh850-crc";
			reg = <0xffd8e000 0xb8>;
			channel = <1>;
			status = "disabled";
		};

		crc2: crc0@ffd40200 {
			compatible = "renesas,rh850-crc";
			reg = <0xffd40200 0xb8>;
			channel = <2>;
			status = "disabled";
		};

		crc3: crc0@ffd8e200 {
			compatible = "renesas,rh850-crc";
			reg = <0xffd8e200 0xb8>;
			channel = <3>;
			status = "disabled";
		};

		crc4: crc0@ffd40400 {
			compatible = "renesas,rh850-crc";
			reg = <0xffd40400 0xb8>;
			channel = <4>;
			status = "disabled";
		};

		crc5: crc0@ffd8e400 {
			compatible = "renesas,rh850-crc";
			reg = <0xffd8e400 0xb8>;
			channel = <5>;
			status = "disabled";
		};

		crc6: crc0@ffd40600 {
			compatible = "renesas,rh850-crc";
			reg = <0xffd40600 0xb8>;
			channel = <6>;
			status = "disabled";
		};

		crc7: crc0@ffd8e600 {
			compatible = "renesas,rh850-crc";
			reg = <0xffd8e600 0xb8>;
			channel = <7>;
			status = "disabled";
		};

		adcka: adc@ff9a2000 {
			compatible = "renesas,rh850-adck";
			reg = <0xff9a2000 0x1000>;
			renesas,unit = <0>;
			interrupts = <69 1>, <70 1>, <71 1>, <72 1>, <73 1>, <68 1>;
			interrupt-names = "sg0", "sg1", "sg2", "sg3", "sg4", "error";
			interrupt-parent = <&intc2>;
			clocks = <&cgc RH850_PCLK(ADCK_AWO, 0, ADCK)>;
			#io-channel-cells = <1>;
			#address-cells = <1>;
			#size-cells = <0>;
			renesas,th-supported-mask = <0x0f>;
			renesas,physical-channel-mask = <0xffffffff 0x00000003>;
			status = "disabled";
		};

		adck1: adc@fff20000 {
			compatible = "renesas,rh850-adck";
			reg = <0xfff20000 0x1000>;
			renesas,unit = <1>;
			interrupts = <371 1>, <372 1>, <373 1>, <374 1>, <375 1>, <370 1>;
			interrupt-names = "sg0", "sg1", "sg2", "sg3", "sg4", "error";
			interrupt-parent = <&intc2>;
			clocks = <&cgc RH850_PCLK(ADCK_ISO, 0, ADCK)>;
			#io-channel-cells = <1>;
			#address-cells = <1>;
			#size-cells = <0>;
			renesas,th-supported-mask = <0x0f>;
			renesas,physical-channel-mask = <0xffffffff 0x00000003>;
			status = "disabled";
		};

		rtc0: rtc@ff997000 {
			compatible = "renesas,rh850-rtc";
			reg = <0xff997000 0x4b>;
			interrupt-parent = <&intc2>;
			interrupts = <233 1>, <234 1>, <235 1>;
			interrupt-names = "one_second", "alarm", "periodic";
			clock-frequency = <32768>;
			alarms-count = <1>;
			status = "disabled";
		};

		iic0: iic0@ff974000 {
			compatible = "renesas,rh850-iic";
			reg = <0xff974000 0x400>;
			interrupts = <262 1>, <263 1>, <271 1>, <269 1>;
			interrupt-names = "rxi", "txi", "eri", "tei";
			interrupt-parent = <&intc2>;
			clocks = <&cgc RH850_PCLK(RI3C, 0, SBUS)>;
			#address-cells = <1>;
			#size-cells = <0>;
			channel = <0>;
			status = "disabled";
		};

		iic1: iic1@ff974800 {
			compatible = "renesas,rh850-iic";
			reg = <0xff974800 0x400>;
			interrupts = <275 1>, <276 1>, <284 1>, <282 1>;
			interrupt-names = "rxi", "txi", "eri", "tei";
			interrupt-parent = <&intc2>;
			clocks = <&cgc RH850_PCLK(RI3C, 1, SBUS)>;
			#address-cells = <1>;
			#size-cells = <0>;
			channel = <1>;
			status = "disabled";
		};

		iic2: iic2@ff975000 {
			compatible = "renesas,rh850-iic";
			reg = <0xff975000 0x400>;
			interrupts = <288 1>, <289 1>, <297 1>, <295 1>;
			interrupt-names = "rxi", "txi", "eri", "tei";
			interrupt-parent = <&intc2>;
			clocks = <&cgc RH850_PCLK(RI3C, 2, SBUS)>;
			#address-cells = <1>;
			#size-cells = <0>;
			channel = <2>;
			status = "disabled";
		};

		ssif0: i2s@ffd8f800 {
			compatible = "renesas,rh850-i2s-ssif";
			reg = <0xffd8f800 0x3c>;
			interrupts = <309 1>, <310 1>, <311 1>;
			interrupt-names = "ssi_txi", "ssi_rxi", "ssi_inti";
			interrupt-parent = <&intc2>;
			channel = <0>;
			clocks = <&cgc RH850_PCLK(SSIF, 0, PCLK)>;
			clock-names = "pclk";
			full-duplex;
			status = "disabled";
		};

		ssif1: i2s@ffd76000 {
			compatible = "renesas,rh850-i2s-ssif";
			reg = <0xffd76000 0x3c>;
			interrupts = <312 1>, <313 1>, <314 1>;
			interrupt-names = "ssi_txi", "ssi_rxi", "ssi_inti";
			interrupt-parent = <&intc2>;
			channel = <1>;
			clocks = <&cgc RH850_PCLK(SSIF, 1, PCLK)>;
			clock-names = "pclk";
			full-duplex;
			status = "disabled";
		};

		sent0: sent@ffd33600 {
			compatible = "renesas,rh850-sent";
			reg = <0xffd33600 0x64>;
			unit = <0>;
			interrupts = <209 1>, <211 1>;
			interrupt-names = "rxi", "eri";
			interrupt-parent = <&intc2>;
			clocks = <&cgc RH850_PCLK(RSENT, 0, HSB)>;
			#address-cells = <1>;
			#size-cells = <0>;
			status = "disabled";

			sent0_ch0: channel@0 {
				reg = <0>;
				status = "disabled";
			};
		};

		sent1: sent@ffd8d100 {
			compatible = "renesas,rh850-sent";
			reg = <0xffd8d100 0x64>;
			unit = <1>;
			interrupts = <210 1>, <212 1>;
			interrupt-names = "rxi", "eri";
			interrupt-parent = <&intc2>;
			clocks = <&cgc RH850_PCLK(RSENT, 1, HSB)>;
			#address-cells = <1>;
			#size-cells = <0>;
			status = "disabled";

			sent1_ch0: channel@0 {
				reg = <0>;
				status = "disabled";
			};
		};

		sent2: sent@ffd33700 {
			compatible = "renesas,rh850-sent";
			reg = <0xffd33700 0x64>;
			unit = <2>;
			interrupts = <470 1>, <476 1>;
			interrupt-names = "rxi", "eri";
			interrupt-parent = <&intc2>;
			clocks = <&cgc RH850_PCLK(RSENT, 2, HSB)>;
			#address-cells = <1>;
			#size-cells = <0>;
			status = "disabled";

			sent2_ch0: channel@0 {
				reg = <0>;
				status = "disabled";
			};
		};

		sent3: sent@ffd8d200 {
			compatible = "renesas,rh850-sent";
			reg = <0xffd8d200 0x64>;
			unit = <3>;
			interrupts = <471 1>, <477 1>;
			interrupt-names = "rxi", "eri";
			interrupt-parent = <&intc2>;
			clocks = <&cgc RH850_PCLK(RSENT, 3, HSB)>;
			#address-cells = <1>;
			#size-cells = <0>;
			status = "disabled";

			sent3_ch0: channel@0 {
				reg = <0>;
				status = "disabled";
			};
		};

		sent4: sent@ffd33800 {
			compatible = "renesas,rh850-sent";
			reg = <0xffd33800 0x64>;
			unit = <4>;
			interrupts = <472 1>, <478 1>;
			interrupt-names = "rxi", "eri";
			interrupt-parent = <&intc2>;
			clocks = <&cgc RH850_PCLK(RSENT, 4, HSB)>;
			#address-cells = <1>;
			#size-cells = <0>;
			status = "disabled";

			sent4_ch0: channel@0 {
				reg = <0>;
				status = "disabled";
			};
		};
	};

	/* External CAN clock - to be overridden by boards that provide it */
	can_clk: can-clk {
		compatible = "fixed-clock";
		clock-frequency = <0>;
		#clock-cells = <0>;
	};
};
